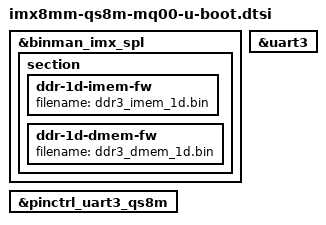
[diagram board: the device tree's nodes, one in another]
// SPDX-License-Identifier: (GPL-2.0 OR MIT)
/*
 * Copyright (C) 2020 Lothar Waßmann <LW@KARO-electronics.de>
 *
 */

#include "imx8mm-karo-u-boot.dtsi"
#include "imx8m-qs8m-u-boot.dtsi"

&binman_imx_spl {
	section {
		ddr-1d-imem-fw {
			filename = "ddr3_imem_1d.bin";
		};

		ddr-1d-dmem-fw {
			filename = "ddr3_dmem_1d.bin";
		};

		/delete-node/ ddr-2d-imem-fw;

		/delete-node/ ddr-2d-dmem-fw;
	};
};

&pinctrl_uart3_qs8m {
	bootph-all;
};

&uart3 {
	bootph-all;
};
